# STM32WL3Rx register map
File version: 1.0
Registers are 32-bit, read-write, reset 0x0 unless marked. A register's access mark holds for its fields unless they carry their own. Offsets are from the block's base; [hi:lo] are bit positions.

## DBGMCU — MCU debug component (DBGMCU)
Base 0x40008000
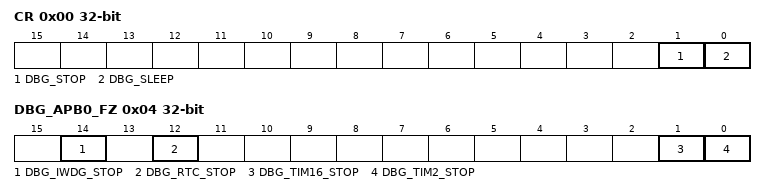
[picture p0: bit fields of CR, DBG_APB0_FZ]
0x00 CR — (@ 0x00000000) CR register
  [1] DBG_STOP, [0] DBG_SLEEP
0x04 DBG_APB0_FZ — (@ 0x00000004) DBG_APB0_FZ register
  [14] DBG_IWDG_STOP, [12] DBG_RTC_STOP, [1] DBG_TIM16_STOP, [0] DBG_TIM2_STOP
0x08 DBG_APB1_FZ — (@ 0x00000008) DBG_APB1_FZ register
  [21] DBG_I2C1_STOP

## I2C1 — Inter-integrated circuit (I2C)
Base 0x41000000
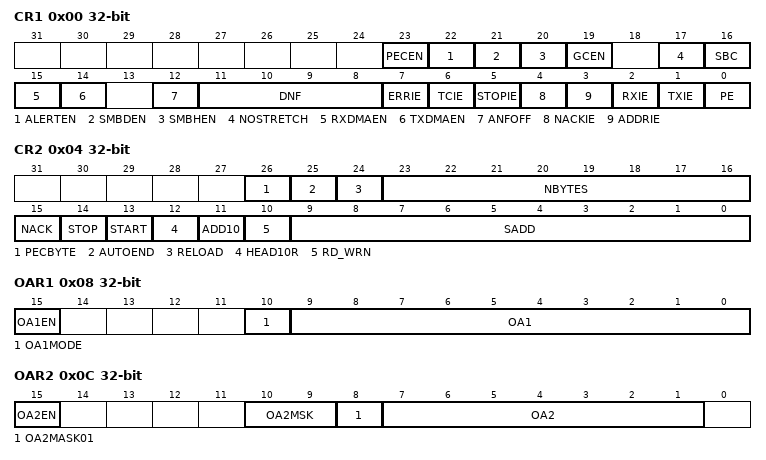
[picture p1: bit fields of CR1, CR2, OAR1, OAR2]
0x00 CR1 — (@ 0x00000000) Control register 1
  [23] PECEN, [22] ALERTEN, [21] SMBDEN, [20] SMBHEN, [19] GCEN, [17] NOSTRETCH, [16] SBC, [15] RXDMAEN, [14] TXDMAEN, [12] ANFOFF, [11:8] DNF, [7] ERRIE, [6] TCIE, [5] STOPIE, [4] NACKIE, [3] ADDRIE, [2] RXIE, [1] TXIE, [0] PE
0x04 CR2 — (@ 0x00000004) Control register 2
  [26] PECBYTE
  [25] AUTOEND
  [24] RELOAD
  [23:16] NBYTES
  [15] NACK
    0=ACK (ACK is sent after current received byte.); 1=NACK (NACK is sent after current received byte.)
  [14] STOP
  [13] START
  [12] HEAD10R
  [11] ADD10
    0=MODE_7BIT (Master operates in 7-bit addressing mode.); 1=MODE_10BIT (Master operates in 10-bit addressing mode.)
  [10] RD_WRN
    0=WRITE (Master request a write transfer.); 1=READ (Master request a read transfer.)
  [9:0] SADD
0x08 OAR1 — (@ 0x00000008) Own address register 1
  [15] OA1EN, [10] OA1MODE, [9:0] OA1
0x0C OAR2 — (@ 0x0000000C) Own address register 2
  [15] OA2EN
  [10:9] OA2MSK
  [8] OA2MASK01 — OA2[1] is masked, Only OA2[7:2] are compared
  [7:1] OA2
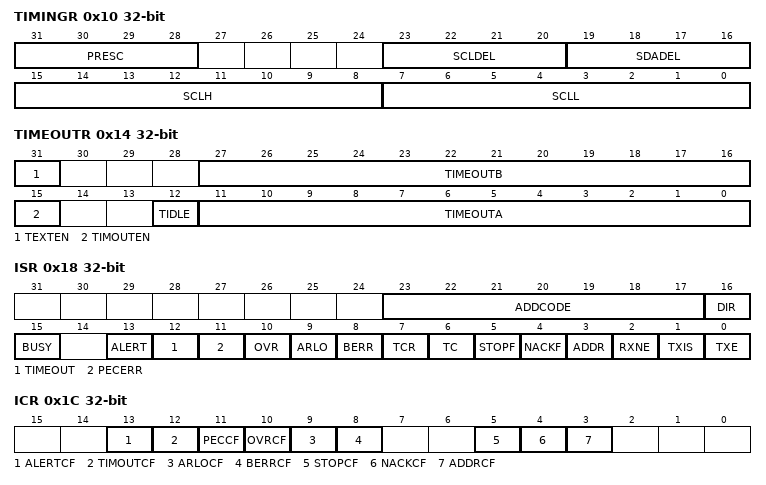
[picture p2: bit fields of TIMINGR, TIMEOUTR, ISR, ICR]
0x10 TIMINGR — (@ 0x00000010) Timing register
  [31:28] PRESC, [23:20] SCLDEL, [19:16] SDADEL, [15:8] SCLH, [7:0] SCLL
0x14 TIMEOUTR — (@ 0x00000014) Timeout register
  [31] TEXTEN
  [27:16] TIMEOUTB
  [15] TIMOUTEN
  [12] TIDLE
    0=SCL_LOW; 1=SDA_SCL_HIGH
  [11:0] TIMEOUTA
0x18 ISR — (@ 0x00000018) Interrupt and Status register
  [23:17] ADDCODE
  [16] DIR
    0=WRITE; 1=READ
  [15] BUSY
  [13] ALERT
  [12] TIMEOUT
  [11] PECERR
  [10] OVR
  [9] ARLO
  [8] BERR
  [7] TCR
  [6] TC
  [5] STOPF
  [4] NACKF
  [3] ADDR
  [2] RXNE
  [1] TXIS
  [0] TXE
0x1C ICR — (@ 0x0000001C) Interrupt clear register
  [13] ALERTCF, [12] TIMOUTCF, [11] PECCF, [10] OVRCF, [9] ARLOCF, [8] BERRCF, [5] STOPCF, [4] NACKCF, [3] ADDRCF
0x20 PECR — (@ 0x00000020) PEC register
  [7:0] PEC
0x24 RXDR — (@ 0x00000024) Receive data register
  [7:0] RXDATA
0x28 TXDR — (@ 0x00000028) Transmit data register
  [7:0] TXDATA

## LPUART1 — Universal synchronous asynchronous receiver transmitter (USART)
Base 0x41005000
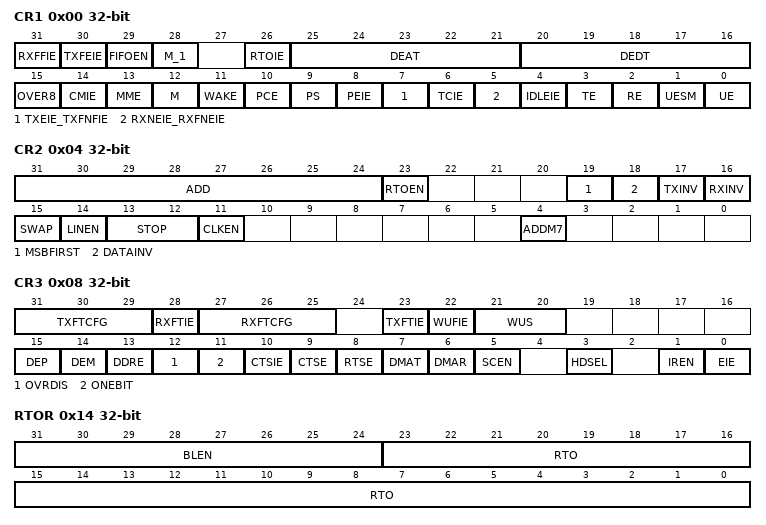
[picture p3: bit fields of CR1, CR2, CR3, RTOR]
0x00 CR1 — (@ 0x00000000) Control register 1
  [31] RXFFIE
  [30] TXFEIE
  [29] FIFOEN
  [28] M_1
  [26] RTOIE
  [25:21] DEAT
  [20:16] DEDT
  [15] OVER8
    0=OVERSAMPLING_16 (Oversampling by 16); 1=OVERSAMPLING_8 (Oversampling by 8)
  [14] CMIE
  [13] MME
  [12] M
  [11] WAKE
    0=IDLELINE (LPUART wake up from Mute mode on Idle Line); 1=ADDRESSMARK (LPUART wake up from Mute mode on Address Mark)
  [10] PCE
  [9] PS
  [8] PEIE
  [7] TXEIE_TXFNFIE
  [6] TCIE
  [5] RXNEIE_RXFNEIE
  [4] IDLEIE
  [3] TE
  [2] RE
  [1] UESM
  [0] UE
0x04 CR2 — (@ 0x00000004) Control register 2
  [31:24] ADD
  [23] RTOEN
  [19] MSBFIRST
    0=LSBFIRST; 1=MSBFIRST
  [18] DATAINV
    0=POSITIVE; 1=NEGATIVE
  [17] TXINV
    0=STANDARD (TX pin signal works using the standard logic levels); 1=INVERTED (TX pin signal values are inverted.)
  [16] RXINV
    0=STANDARD (RX pin signal works using the standard logic levels); 1=INVERTED (RX pin signal values are inverted.)
  [15] SWAP
    0=STANDARD (TX/RX pins are used as defined in standard pinout); 1=SWAPPED (TX and RX pins functions are swapped.)
  [14] LINEN
  [13:12] STOP
    0=STOPBITS_1 (1 stop bit); 2=STOPBITS_2 (2 stop bits); 1=STOPBITS_0_5 (0.5 stop bit); 3=STOPBITS_1_5 (1.5 stop bits)
  [11] CLKEN
  [4] ADDM7
    0=DETECT_4B (4-bit address detection method selected); 1=DETECT_7B (7-bit address detection (in 8-bit data mode) method selected)
0x08 CR3 — (@ 0x00000008) Control register 3
  [31:29] TXFTCFG
  [28] RXFTIE
  [27:25] RXFTCFG
  [23] TXFTIE
  [22] WUFIE
  [21:20] WUS
    0=ADDRESS (Wake up active on address match); 2=STARTBIT (Wake up active on Start bit detection); 3=RXNE (Wake up active on RXNE)
  [15] DEP
    0=HIGH (DE signal is active high); 1=LOW (DE signal is active low)
  [14] DEM
  [13] DDRE
  [12] OVRDIS
  [11] ONEBIT
  [10] CTSIE
  [9] CTSE
  [8] RTSE
  [7] DMAT
  [6] DMAR
  [5] SCEN
  [3] HDSEL
  [1] IREN
  [0] EIE
0x0C BRR — (@ 0x0000000C) Baud rate register
  [19:0] BRR
0x14 RTOR — (@ 0x00000014) Receiver timeout register
  [31:24] BLEN, [23:0] RTO
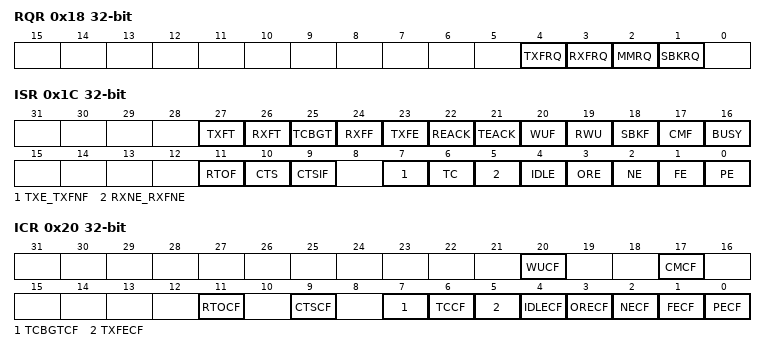
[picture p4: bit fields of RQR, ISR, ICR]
0x18 RQR — (@ 0x00000018) Request register
  [4] TXFRQ, [3] RXFRQ, [2] MMRQ, [1] SBKRQ
0x1C ISR — (@ 0x0000001C) Interrupt & status register
  [27] TXFT, [26] RXFT, [25] TCBGT, [24] RXFF, [23] TXFE, [22] REACK, [21] TEACK, [20] WUF, [19] RWU, [18] SBKF, [17] CMF, [16] BUSY, [11] RTOF, [10] CTS, [9] CTSIF, [7] TXE_TXFNF, [6] TC, [5] RXNE_RXFNE, [4] IDLE, [3] ORE, [2] NE, [1] FE, [0] PE
0x20 ICR — (@ 0x00000020) Interrupt flag clear register
  [20] WUCF, [17] CMCF, [11] RTOCF, [9] CTSCF, [7] TCBGTCF, [6] TCCF, [5] TXFECF, [4] IDLECF, [3] ORECF, [2] NECF, [1] FECF, [0] PECF
0x24 RDR — (@ 0x00000024) Receive data register
  [8:0] RDR
0x28 TDR — (@ 0x00000028) Transmit data register
  [8:0] TDR
0x2C PRESC — (@ 0x0000002C) Prescaler register
  [3:0] PRESCALER
    0=DIV1 (Input clock not divided); 1=DIV2 (Input clock divided by 2); 2=DIV4 (Input clock divided by 4); 3=DIV6; 4=DIV8 (Input clock divided by 8); 5=DIV10; 6=DIV12; 7=DIV16; 8=DIV32 (Input clock divided by 32); 9=DIV64; 10=DIV128; 11=DIV256
